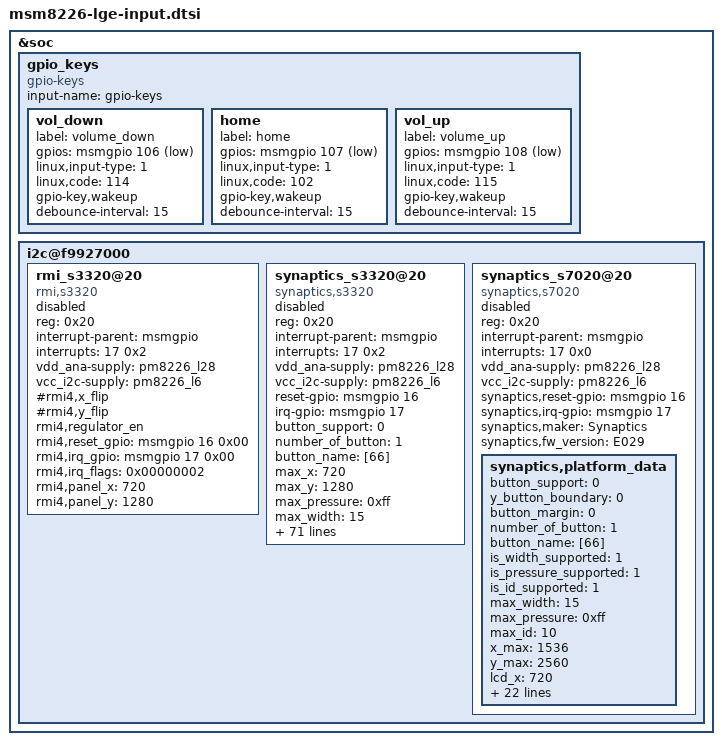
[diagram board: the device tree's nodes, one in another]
/* Copyright (c) 2012, Code Aurora Forum. All rights reserved.
 *
 * This program is free software; you can redistribute it and/or modify
 * it under the terms of the GNU General Public License version 2 and
 * only version 2 as published by the Free Software Foundation.
 *
 * This program is distributed in the hope that it will be useful,
 * but WITHOUT ANY WARRANTY; without even the implied warranty of
 * MERCHANTABILITY or FITNESS FOR A PARTICULAR PURPOSE.  See the
 * GNU General Public License for more details.
 */

&soc {

	gpio_keys {
		compatible = "gpio-keys";
		input-name = "gpio-keys";

		vol_down {
			label = "volume_down";
			gpios = <&msmgpio 106 0x1>;
			linux,input-type = <1>;
			linux,code = <114>;
			gpio-key,wakeup;
			debounce-interval = <15>;
		};

		home {
			label = "home";
			gpios = <&msmgpio 107 0x1>;
			linux,input-type = <1>;
			linux,code = <102>;
			gpio-key,wakeup;
			debounce-interval = <15>;
		};

		vol_up {
			label = "volume_up";
			gpios = <&msmgpio 108 0x1>;
			linux,input-type = <1>;
			linux,code = <115>;
			gpio-key,wakeup;
			debounce-interval = <15>;
		};

            
	};

	i2c@f9927000 { /* BLSP1 QUP5 */

				rmi_s3320@20 {
					compatible = "rmi,s3320";
					status = "disable";
					reg = <0x20>;                              // check!!
					interrupt-parent = <&msmgpio>;
					interrupts = <17 0x2>;                   //check!!
					vdd_ana-supply = <&pm8226_l28>;
					vcc_i2c-supply = <&pm8226_l6>;
					#rmi4,x_flip;
					#rmi4,y_flip;
					rmi4,regulator_en;
					rmi4,reset_gpio = <&msmgpio 16 0x00>;
					rmi4,irq_gpio = <&msmgpio 17 0x00>;
					rmi4,irq_flags = <0x00000002>;     //check!!
					rmi4,panel_x = <720>;
					rmi4,panel_y = <1280>;
				};
				
				synaptics_s3320@20 {
					compatible = "synaptics,s3320";
					status = "disable";
					reg = <0x20>;
					interrupt-parent = <&msmgpio>;
					interrupts = <17 0x2>;
					vdd_ana-supply = <&pm8226_l28>;
					vcc_i2c-supply = <&pm8226_l6>;
					reset-gpio = <&msmgpio 16 0x00>;
					irq-gpio = <&msmgpio 17 0x00>;


					/*Caps*/
					button_support = <0>;
					number_of_button = <1>;
					button_name = [66];
					
					max_x = <720>;
					max_y = <1280>;
			
					max_pressure = <0xff>;
					max_width = <15>;
					max_orientation = <1>;
					max_id = <10>;
					
					/*role*/
					protocol_type = <1>;  /* ? */
					
					report_mode = <0>;
					delta_pos_threshold = <1>;   /* ? */
					report_period = <10000000>;
					booting_delay = <60>;
					reset_delay = <10>;
					wake_up_by_touch = <1>;
					use_sleep_mode = <0>;
					thermal_check = <1>;
					palm_ctrl_mode = <0>;
					mini_os_finger_amplitude = <41>;
					irqflags = <0x00000002>;
					bouncing.enable = <0>;
					grip.enable = <0>;
					grip.edge_region = <5>;
					grip.max_delta = <10>;
					grip.width_ratio = <2>;
					accuracy.enable = <0>;
					accuracy.min_delta = <3>;
					accuracy.curr_ratio = <5>;
					accuracy.min_pressure = <50>;
					jitter.enable = <0>;
					jitter.curr_ratio = <115>;
					quickcover.enable = <0>;
					quickcover.X1 = <148>;
					quickcover.X2 = <1292>;
					quickcover.Y1 = <0>;
					quickcover.Y2 = <1101>;
					crack.enable = <0>;
					crack.min.cap = <300>;
					/*ghost_detection -S*/
					ghost_detection_enable = <0>;
					ghost_detection_chk_cnt = <3>;
					jitter_value = <10>;
					ta_noise_chk = <0>;
					incoming_call_chk = <0>;
					first_finger_chk = <1>;
					first_finger_time = <200>;
					pressure_zero_chk = <1>;
					ta_debouncing_chk = <0>;
					ta_debouncing_cnt =<2>;
					ta_debouncing_finger_num = <2>;
					press_interval_chk = <1>;
					press_interval = <29>;
					diff_fingers_chk = <1>;
					diff_finger_num = <5>;
					subtraction_finger_chk = <0>;
					subtraction_time = <11>;
					subtraction_finger_cnt = <5>;
					long_press_chk = <1>;
					long_press_chk_time = <10>;
					long_press_cnt = <700>;
					button_chk = <0>;
					button_int_num = <6>;
					button_duration = <100>;
					rebase_repetition_chk = <1>;
					rebase_since_init = <3>;
					rebase_since_rebase = <5>;
					use_lpwg_all = <0>;
					/*ghost_detection -E*/
					/*pwr*/
					use_regulator = <1>;
					vdd = "vdd_ana";
					vdd_voltage = <3100000>;
					vio = "vcc_i2c";
					vio_voltage = <1800000>;
					/*firmware*/
					need_upgrade = <0>;
					/* Rx & Tx cap*/
					tx_cap = <5 10 2 9 7 5 1 2 2 1 10 2 3 83 7 2 8 0 10 0 5 8 4 8 6 40 88>;  /*  ghost rebase relate  */
					rx_cap = <53 12 15 26 28 13 27 25 4 15 5 6 22 9 44>;
					/* 1:sd. 2:ref_rebase. 3:TX. 4:RX.*/
					ref_chk_option = <0 0 1 1>;    /* check  */
			};
					
		
		synaptics_s7020@20 {
			compatible = "synaptics,s7020";
			status = "disable";
			reg = <0x20>;
			interrupt-parent = <&msmgpio>;
			interrupts = <17 0x0>;
			vdd_ana-supply = <&pm8226_l28>;
			vcc_i2c-supply = <&pm8226_l6>;
			synaptics,reset-gpio = <&msmgpio 16 0x00>;
			synaptics,irq-gpio = <&msmgpio 17 0x00>;
			synaptics,maker = "Synaptics";
			synaptics,fw_version = "E029";
			synaptics,platform_data	{
				/*Caps*/
				button_support = <0>;
				y_button_boundary = <0>;
				button_margin = <0>;
				number_of_button = <1>;
				button_name = [66];
				is_width_supported = <1>;
				is_pressure_supported	= <1>;
				is_id_supported = <1>;
				max_width = <15>;
				max_pressure = <0xff>;
				max_id = <10>;
				/*LCD Resolution */
				x_max = <1536>;
				y_max	= <2560>;
				lcd_x	= <720>;
				lcd_y	= <1280>;

				/*Role*/
				operation_mode = <1>; /* Interrupt Mode */
				report_mode = <0>;
				key_type = <1>;
				delta_pos_threshold = <0>;
				orientation = <0>;
				report_period = <10000000>;
				booting_delay = <250>;
				reset_delay = <20>;
				suspend_pwr = <0>;
				resume_pwr = <1>;
				jitter_filter_enable = <1>;
				jitter_curr_ratio = <26>;
				accuracy_filter_enable = <1>;
				ghost_detection_enable = <1>;
				irqflags = <0x00000002>;
				ta_debouncing_count = <2>;
				/*pwr*/
				use_regulator = <0>;
				vdd = "vdd_ana";
				vdd_voltage = <2800000>; /*for EVB, normal Board is 3.1V*/
				vio = "vcc_i2c";
                		vio_voltage = <1800000>;
			};
		};
	};
};
